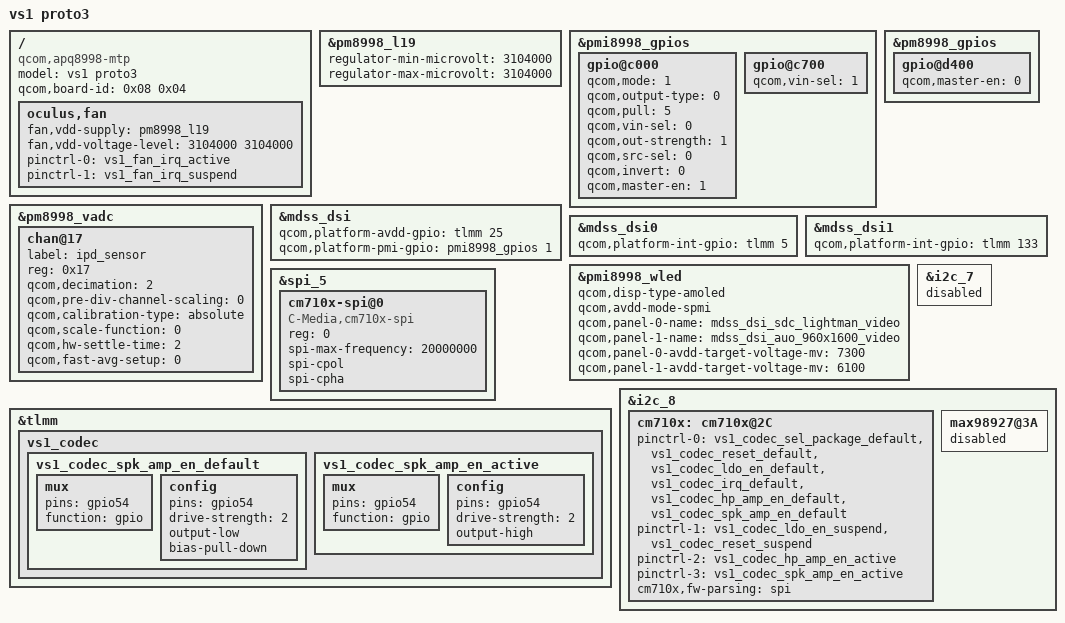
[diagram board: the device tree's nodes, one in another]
/* Copyright (c) 2016, The Linux Foundation. All rights reserved.
 *
 * This program is free software; you can redistribute it and/or modify
 * it under the terms of the GNU General Public License version 2 and
 * only version 2 as published by the Free Software Foundation.
 *
 * This program is distributed in the hope that it will be useful,
 * but WITHOUT ANY WARRANTY; without even the implied warranty of
 * MERCHANTABILITY or FITNESS FOR A PARTICULAR PURPOSE.  See the
 * GNU General Public License for more details.
 */


/dts-v1/;

#include "../qcom/apq8098-v2.1.dtsi"
#include "../qcom/msm8998-mdss-panels.dtsi"
#include "../qcom/msm8998-mtp.dtsi"
#include "vs1-camera.dtsi"
#include "vs1-misc.dtsi"
#include "vs1-serial.dtsi"
#include "vs1.dtsi"

/ {
	model = "vs1 proto3";
	compatible = "qcom,apq8998-mtp", "qcom,apq8998", "qcom,mtp";
	qcom,board-id = <0x08 0x04>;

	oculus,fan {
		/delete-property/ fan-power;
		fan,vdd-supply = <&pm8998_l19>;
		fan,vdd-voltage-level = <3104000 3104000>;
		pinctrl-0 = <&vs1_fan_irq_active>;
		pinctrl-1 = <&vs1_fan_irq_suspend>;
	};
};

&pm8998_l19 {
	regulator-min-microvolt = <3104000>;
	regulator-max-microvolt = <3104000>;
};

&pmi8998_gpios {
	/* GPIO 1 for WLED power enable */
	gpio@c000 {
		qcom,mode = <1>;
		qcom,output-type = <0>;
		qcom,pull = <5>;
		qcom,vin-sel = <0>;
		qcom,out-strength = <1>;
		qcom,src-sel = <0>;
		qcom,invert = <0>;
		qcom,master-en = <1>;
		status = "okay";
	};

	gpio@c700 {
		qcom,vin-sel = <1>;
		status = "okay";
	};
};

&pm8998_gpios {
	/delete-node/ gpio@d100;

	gpio@d400 {
		qcom,master-en = <0>;
		status = "okay";
	};
};

&pm8998_vadc {
	chan@17 {
		label = "ipd_sensor";	/* Channel name used for sysfs entry */
		reg = <0x17>;		/* AMUX channel number */
		qcom,decimation = <2>;	/* 2K Sampling rate  */
		qcom,pre-div-channel-scaling = <0>;	/* 1:1 scaling */
		qcom,calibration-type = "absolute";
		qcom,scale-function = <0>;	/* Default scaling to convert raw adc code to voltage */
		qcom,hw-settle-time = <2>;	/* 200us Settling period for the channel before ADC read */
		qcom,fast-avg-setup = <0>;
	};
};

&mdss_dsi {
	qcom,platform-avdd-gpio = <&tlmm 25 0>;
	qcom,platform-pmi-gpio = <&pmi8998_gpios 1 0>;
};

&mdss_dsi0 {
	qcom,platform-int-gpio = <&tlmm 5 0>;
};

&mdss_dsi1 {
	qcom,platform-int-gpio=<&tlmm 133 0>;
};

&pmi8998_wled {
	qcom,disp-type-amoled;
	qcom,avdd-mode-spmi;
	qcom,panel-0-name = "mdss_dsi_sdc_lightman_video";
	qcom,panel-1-name = "mdss_dsi_auo_960x1600_video";
	qcom,panel-0-avdd-target-voltage-mv = <7300>;
	qcom,panel-1-avdd-target-voltage-mv = <6100>;
};

&i2c_7 {
	status = "disabled";
	/delete-node/ qcom,smb138x@8;
};

&spi_5 {
	status = "okay";
	cm710x-spi@0 {
		compatible = "C-Media,cm710x-spi";
		reg = <0>;
		spi-max-frequency = <20000000>;
		spi-cpol;
		spi-cpha;
	};
};

&tlmm {
	vs1_codec {
		vs1_codec_spk_amp_en_default: vs1_codec_spk_amp_en_default {
			mux {
				pins = "gpio54";
				function = "gpio";
			};
			config {
				pins = "gpio54";
				drive-strength = <2>;
				output-low;
				bias-pull-down;
			};
		};

		vs1_codec_spk_amp_en_active: vs1_codec_spk_amp_en_active {
			mux {
				pins = "gpio54";
				function = "gpio";
			};
			config {
				pins = "gpio54";
				drive-strength = <2>;
				output-high;
			};
		};
	};
};

&i2c_8 {
	cm710x: cm710x@2C {
		pinctrl-names = "vs1_codec_default", "vs1_codec_suspend",
			"vs1_codec_hp_en", "vs1_codec_spk_en";
		pinctrl-0 = <&vs1_codec_sel_package_default
			&vs1_codec_reset_default
			&vs1_codec_ldo_en_default
			&vs1_codec_irq_default
			&vs1_codec_hp_amp_en_default
			&vs1_codec_spk_amp_en_default>;
		pinctrl-1 = <&vs1_codec_ldo_en_suspend
			&vs1_codec_reset_suspend>;
		pinctrl-2 = <&vs1_codec_hp_amp_en_active>;
		pinctrl-3 = <&vs1_codec_spk_amp_en_active>;

		cm710x,fw-parsing = "spi";
	};

	max98927@3A {
		status = "disabled";
	};
};
